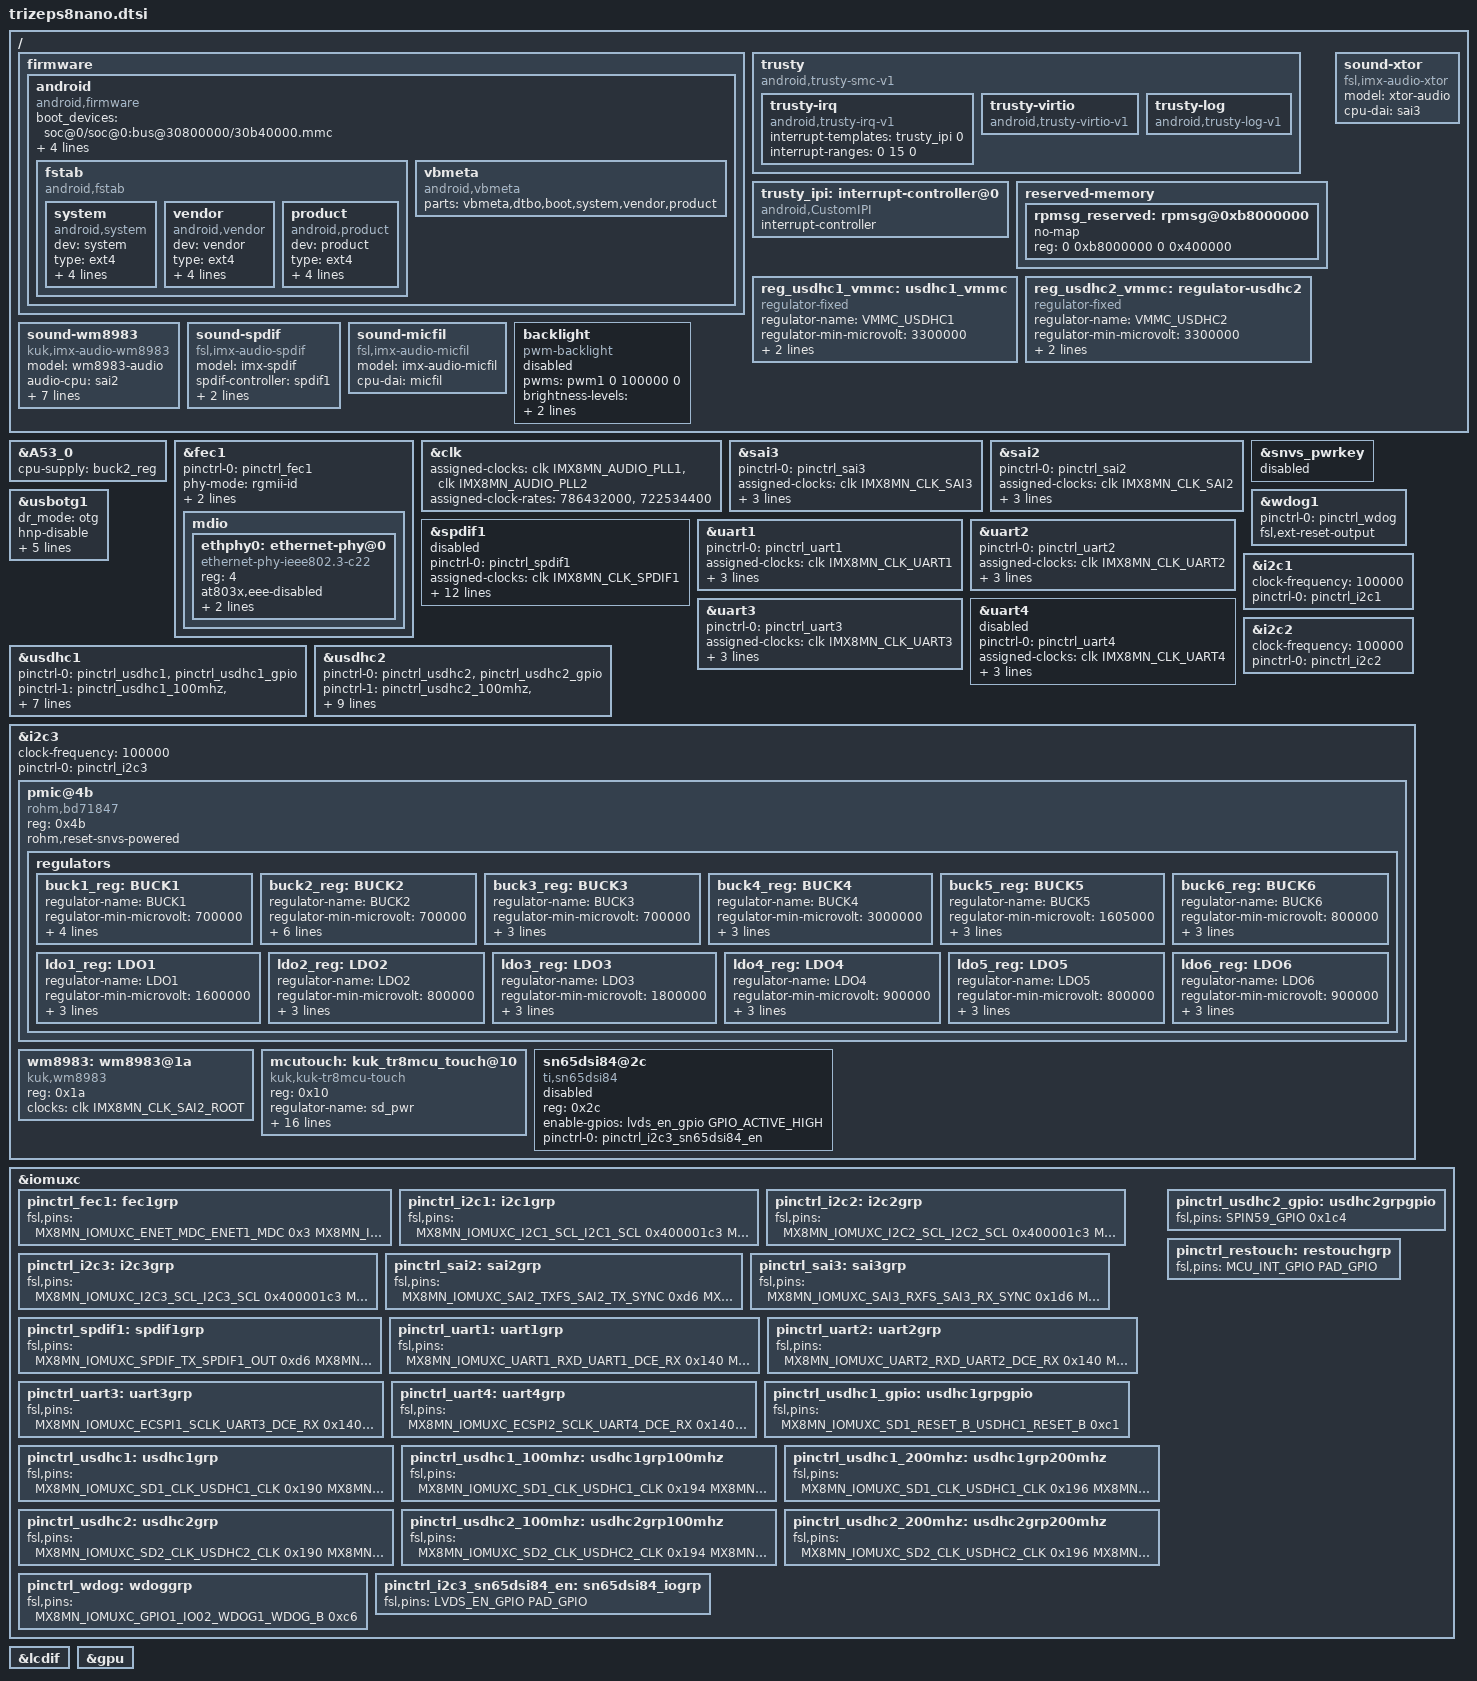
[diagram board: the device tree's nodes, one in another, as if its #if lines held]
/*
 * Copyright 2020 Keith & Koep GmbH
 */

 /*
Switches:
    TRIZEPS8NANO_USDHC1_VQMMC_MCU		For UHS: Control VQMMC voltage of internal uSD-Card.
    TRIZEPS8NANO_USDHC2_VQMMC_MCU		For UHS: Control VQMMC voltage of external uSD-Card. 
    There is only one VQMMC-switch on the Trizeps module. 
    Module with eMMC:   VQMMC of eMMC fixed to +1V8 and VQMMC of ext. uSD fixed to +3V3   
                        Special mounting exist to switch ext. uSD voltage: Use TRIZEPS8NANO_USDHC2_VQMMC_MCU in that case.
    Module with uSD:    VQMMC of int. uSD switchable (+3V3/+1V8) and VQMMC of ext. uSD fixed to +3V3. 
                        May use TRIZEPS8NANO_USDHC1_VQMMC_MCU to allow UHS.
    
    ETHERNET_ONLY_100MBIT				Reduce Ethernet to 100MBit in case extra lanes for 1GBit are not connected on the baseboard.

    TRIZEPS8NANO_BT_SCO_XTOR			Special audio-driver for Bluetooth.

*/

#include "imx8mn.dtsi"
#include "trizeps8nano-pinfunc.h"

#define TRIZEPS_HOGGRP_COMMON	

/ {
	firmware {
		android {
			compatible = "android,firmware";
			/* default emmc node used for GSI */
			boot_devices = "soc@0/soc@0:bus@30800000/30b40000.mmc";
			/* sd card node which used if androidboot.boot_device_root=mmcblk1 */
			boot_devices_mmcblk1 = "soc@0/soc@0:bus@30800000/30b40000.mmc";
			/* emmc node which used if androidboot.boot_device_root=mmcblk2 */
			boot_devices_mmcblk2 = "soc@0/soc@0:bus@30800000/30b40000.mmc";
			fstab {
				compatible = "android,fstab";
				system {
					compatible = "android,system";
					dev = "system";
					type = "ext4";
					mnt_flags = "noatime,errors=panic,ro,barrier=1,inode_readahead_blks=8";
					fsmgr_flags = "wait,slotselect,avb,avb_keys=/avb/q-gsi.avbpubkey:/avb/r-gsi.avbpubkey:/avb/s-gsi.avbpubkey,logical,first_stage_mount";
				};
				vendor {
					compatible = "android,vendor";
					dev = "vendor";
					type = "ext4";
					mnt_flags = "noatime,errors=panic,ro,barrier=1,inode_readahead_blks=8";
					fsmgr_flags = "wait,slotselect,avb,logical,first_stage_mount";
				};
				product {
					compatible = "android,product";
					dev = "product";
					type = "ext4";
					mnt_flags = "noatime,errors=panic,ro,barrier=1,inode_readahead_blks=8";
					fsmgr_flags = "wait,slotselect,avb,logical,first_stage_mount";
				};
			};
			vbmeta {
				/*we need use FirstStageMountVBootV2 if we enable avb*/
				compatible = "android,vbmeta";
				/*parts means the partition witch can be mount in first stage*/
				parts = "vbmeta,dtbo,boot,system,vendor,product";
			};
		};
	};
};

/ {
	trusty {
		compatible = "android,trusty-smc-v1";
		ranges;
		#address-cells = <2>;
		#size-cells = <2>;
		trusty-irq {
			compatible = "android,trusty-irq-v1";
			interrupt-templates = <&trusty_ipi 0>;
			interrupt-ranges = < 0 15 0>;
		};
		trusty-virtio {
			compatible = "android,trusty-virtio-v1";
		};
		trusty-log {
			compatible = "android,trusty-log-v1";
		};
	};
	trusty_ipi: interrupt-controller@0 {
		compatible = "android,CustomIPI";
		interrupt-controller;
		#interrupt-cells = <1>;
	};
};

/ {
	reserved-memory {
		#address-cells = <2>;
		#size-cells = <2>;
		ranges;

		rpmsg_reserved: rpmsg@0xb8000000 {
			no-map;
			reg = <0 0xb8000000 0 0x400000>;
		};
	};

	reg_usdhc1_vmmc: usdhc1_vmmc {
		compatible = "regulator-fixed";
		regulator-name = "VMMC_USDHC1";
		regulator-min-microvolt = <3300000>;
		regulator-max-microvolt = <3300000>;
		enable-active-high;
	};

	reg_usdhc2_vmmc: regulator-usdhc2 {
		compatible = "regulator-fixed";
		regulator-name = "VMMC_USDHC2";
		regulator-min-microvolt = <3300000>;
		regulator-max-microvolt = <3300000>;
		enable-active-high;
	};

#if defined(TRIZEPS8NANO_BT_SCO_XTOR) && (TRIZEPS8NANO_BT_SCO_XTOR==1)
	sound-xtor {
		compatible = "fsl,imx-audio-xtor";
		model = "xtor-audio";
		cpu-dai = <&sai3>;
		status = "okay";
	};
#else 
	bt_sco_codec: bt_sco_codec {
		#sound-dai-cells = <0>;
		compatible = "linux,bt-sco";
	};

	sound-bt-sco {
		compatible = "simple-audio-card";
		simple-audio-card,name = "bt-sco-audio";
		simple-audio-card,format = "i2s";
		simple-audio-card,bitclock-inversion;
		simple-audio-card,frame-master = <&btcpu>;
		simple-audio-card,bitclock-master = <&btcpu>;

		btcpu: simple-audio-card,cpu {
			sound-dai = <&sai2>;
			dai-tdm-slot-num = <2>;
			dai-tdm-slot-width = <16>;
		};

		simple-audio-card,codec {
			sound-dai = <&bt_sco_codec>;
		};
	};
#endif

	sound-wm8983 {
		compatible = "kuk,imx-audio-wm8983";
		model = "wm8983-audio";
		audio-cpu = <&sai2>;
		audio-codec = <&wm8983>;
		audio-routing =
			"Headphone Jack", "HPL",
			"Headphone Jack", "HPR",
			"Headphone Jack", "OUT4",
			"Speaker", "SPKL",
			"Speaker", "SPKR",
			"LineIn Jack", "L2",
			"LineIn Jack", "R2",
			"Microphone", "LIP",
			"Microphone", "LIN",
			"Microphone", "MICBIAS";
		codec-master;
	};

	sound-spdif {
		compatible = "fsl,imx-audio-spdif";
		model = "imx-spdif";
		spdif-controller = <&spdif1>;
		spdif-out;
		spdif-in;
	};

	sound-micfil {
		compatible = "fsl,imx-audio-micfil";
		model = "imx-audio-micfil";
		cpu-dai = <&micfil>;
	};

	backlight: backlight {
		compatible = "pwm-backlight";
		pwms = <&pwm1 0 100000 0>;
		brightness-levels = < 0  1  2  3  4  5  6  7  8  9
				     10 11 12 13 14 15 16 17 18 19
				     20 21 22 23 24 25 26 27 28 29
				     30 31 32 33 34 35 36 37 38 39
				     40 41 42 43 44 45 46 47 48 49
				     50 51 52 53 54 55 56 57 58 59
				     60 61 62 63 64 65 66 67 68 69
				     70 71 72 73 74 75 76 77 78 79
				     80 81 82 83 84 85 86 87 88 89
				     90 91 92 93 94 95 96 97 98 99
				    100>;
		default-brightness-level = <80>;
		status = "disabled";
 	};
};

&A53_0 {
	cpu-supply = <&buck2_reg>;
};

&fec1 {
	pinctrl-names = "default";
	pinctrl-0 = <&pinctrl_fec1>;
	phy-mode = "rgmii-id";
	phy-handle = <&ethphy0>;
	fsl,magic-packet;
	status = "okay";

	mdio {
		#address-cells = <1>;
		#size-cells = <0>;

		ethphy0: ethernet-phy@0 {
			compatible = "ethernet-phy-ieee802.3-c22";
			reg = <4>;
			at803x,eee-disabled;
			at803x,vddio-1p8v;
#if defined(ETHERNET_ONLY_100MBIT) && (ETHERNET_ONLY_100MBIT==1)
			at803x,100MBit;
#endif            
		};
	};
};

&clk {
	assigned-clocks = <&clk IMX8MN_AUDIO_PLL1>, <&clk IMX8MN_AUDIO_PLL2>;
	assigned-clock-rates = <786432000>, <722534400>;
};

&sai3 {
	pinctrl-names = "default";
	pinctrl-0 = <&pinctrl_sai3>;
	assigned-clocks = <&clk IMX8MN_CLK_SAI3>;
	assigned-clock-parents = <&clk IMX8MN_AUDIO_PLL1_OUT>;
	assigned-clock-rates = <49152000>;
	status = "okay";
};

&sai2 {
	#sound-dai-cells = <0>;
	pinctrl-names = "default";
	pinctrl-0 = <&pinctrl_sai2>;
	assigned-clocks = <&clk IMX8MN_CLK_SAI2>;
	assigned-clock-parents = <&clk IMX8MN_AUDIO_PLL1_OUT>;
	assigned-clock-rates = <24576000>;
	status = "okay";
};

&spdif1 {
	pinctrl-names = "default";
	pinctrl-0 = <&pinctrl_spdif1>;
	assigned-clocks = <&clk IMX8MN_CLK_SPDIF1>;
	assigned-clock-parents = <&clk IMX8MN_AUDIO_PLL1_OUT>;
	assigned-clock-rates = <24576000>;
	clocks = <&clk IMX8MN_CLK_AUDIO_AHB>, <&clk IMX8MN_CLK_24M>,
		<&clk IMX8MN_CLK_SPDIF1>, <&clk IMX8MN_CLK_DUMMY>,
		<&clk IMX8MN_CLK_DUMMY>, <&clk IMX8MN_CLK_DUMMY>,
		<&clk IMX8MN_CLK_AUDIO_AHB>, <&clk IMX8MN_CLK_DUMMY>,
		<&clk IMX8MN_CLK_DUMMY>, <&clk IMX8MN_CLK_DUMMY>,
		<&clk IMX8MN_AUDIO_PLL1_OUT>, <&clk IMX8MN_AUDIO_PLL2_OUT>;
	clock-names = "core", "rxtx0", "rxtx1", "rxtx2", "rxtx3",
		"rxtx4", "rxtx5", "rxtx6", "rxtx7", "spba", "pll8k", "pll11k";
	status = "disabled";
};

&snvs_pwrkey {
	status = "disabled";
};

&uart1 { /* FFUART */
	pinctrl-names = "default";
	pinctrl-0 = <&pinctrl_uart1>;
	assigned-clocks = <&clk IMX8MN_CLK_UART1>;
	assigned-clock-parents = <&clk IMX8MN_SYS_PLL1_80M>;
	fsl,uart-has-rtscts;
	status = "okay";
};

&uart2 { /* BTUART */
	pinctrl-names = "default";
	pinctrl-0 = <&pinctrl_uart2>;
	assigned-clocks = <&clk IMX8MN_CLK_UART2>;
	assigned-clock-parents = <&clk IMX8MN_SYS_PLL1_80M>;
    fsl,uart-has-rtscts;
	status = "okay";
};

&uart3 { /* STUART; optional internal for Bluetooth*/
	pinctrl-names = "default";
	pinctrl-0 = <&pinctrl_uart3>;
	assigned-clocks = <&clk IMX8MN_CLK_UART3>;
	assigned-clock-parents = <&clk IMX8MN_SYS_PLL1_80M>;
	fsl,uart-has-rtscts;
	status = "okay";
};

&uart4 { /* internal UART or SPI to FPGA and MCU*/
	pinctrl-names = "default";
	pinctrl-0 = <&pinctrl_uart4>;
	assigned-clocks = <&clk IMX8MN_CLK_UART4>;
	assigned-clock-parents = <&clk IMX8MN_SYS_PLL1_80M>;
	fsl,uart-has-rtscts;
	status = "disabled";
};


&usbotg1 {
	dr_mode = "otg";
	hnp-disable;
	srp-disable;
	adp-disable;
	usb-role-switch;
	picophy,pre-emp-curr-control = <3>;
	picophy,dc-vol-level-adjust = <7>;
	status = "okay";
};

&usdhc1 {
	pinctrl-names = "default", "state_100mhz", "state_200mhz";
	pinctrl-0 = <&pinctrl_usdhc1>, <&pinctrl_usdhc1_gpio>;
	pinctrl-1 = <&pinctrl_usdhc1_100mhz>, <&pinctrl_usdhc1_gpio>;
	pinctrl-2 = <&pinctrl_usdhc1_200mhz>, <&pinctrl_usdhc1_gpio>;
	bus-width = <8>;
	vmmc-supply = <&reg_usdhc1_vmmc>;
	non-removable;
#if defined(TRIZEPS8NANO_USDHC1_VQMMC_MCU) && (TRIZEPS8NANO_USDHC1_VQMMC_MCU==1)
    vqmmc-supply = <&mcutouch>;
#endif
	status = "okay";
};

&usdhc2 {
	pinctrl-names = "default", "state_100mhz", "state_200mhz";
	pinctrl-0 = <&pinctrl_usdhc2>, <&pinctrl_usdhc2_gpio>;
	pinctrl-1 = <&pinctrl_usdhc2_100mhz>, <&pinctrl_usdhc2_gpio>;
	pinctrl-2 = <&pinctrl_usdhc2_200mhz>, <&pinctrl_usdhc2_gpio>;
	cd-gpios = <spin59_gpio GPIO_ACTIVE_LOW>;
	bus-width = <4>;
	vmmc-supply = <&reg_usdhc2_vmmc>;
	pm-ignore-notify;
	keep-power-in-suspend;
#if defined(TRIZEPS8NANO_USDHC2_VQMMC_MCU) && (TRIZEPS8NANO_USDHC2_VQMMC_MCU==1)
    vqmmc-supply = <&mcutouch>;
#else
    no-1-8-v;
#endif    
	status = "okay";
};

&wdog1 {
	pinctrl-names = "default";
	pinctrl-0 = <&pinctrl_wdog>;
	fsl,ext-reset-output;
	status = "okay";
};

&i2c1 { /* Secondary I2C on SODIMM 94,96 */
	clock-frequency = <100000>;
	pinctrl-names = "default";
	pinctrl-0 = <&pinctrl_i2c1>;
	status = "okay";
};

&i2c2 { /* Secondary I2C on SODIMM 94,96 */
	clock-frequency = <100000>;
	pinctrl-names = "default";
	pinctrl-0 = <&pinctrl_i2c2>;
	status = "okay";
};

&i2c3 { /* Internal I2C */
	clock-frequency = <100000>;
	pinctrl-names = "default";
	pinctrl-0 = <&pinctrl_i2c3>;
	status = "okay";

	pmic@4b {
		compatible = "rohm,bd71847";
		reg = <0x4b>;
		rohm,reset-snvs-powered;

		regulators {
			buck1_reg: BUCK1 {  // VDD_SOC_0V8
				regulator-name = "BUCK1";
				regulator-min-microvolt = <700000>;
				regulator-max-microvolt = <1300000>;
				regulator-boot-on;
				regulator-always-on;
				regulator-ramp-delay = <1250>;
			};

			buck2_reg: BUCK2 {  // VDD_SOC_0V9
				regulator-name = "BUCK2";
				regulator-min-microvolt = <700000>;
				regulator-max-microvolt = <1300000>;
				regulator-boot-on;
				regulator-always-on;
				regulator-ramp-delay = <1250>;
				rohm,dvs-run-voltage = <1000000>;
				rohm,dvs-idle-voltage = <900000>;
			};

			buck3_reg: BUCK3 {  // VDD_DRAM_PU_0V9
				// BUCK5 in datasheet
				regulator-name = "BUCK3";
				regulator-min-microvolt = <700000>;
				regulator-max-microvolt = <1350000>;
				regulator-boot-on;
				regulator-always-on;
			};

			buck4_reg: BUCK4 {  // +3V3_AUX
				// BUCK6 in datasheet
				regulator-name = "BUCK4";
				regulator-min-microvolt = <3000000>;
				regulator-max-microvolt = <3300000>;
				regulator-boot-on;
				regulator-always-on;
			};

			buck5_reg: BUCK5 {  // VDD_1V8
				// BUCK7 in datasheet
				regulator-name = "BUCK5";
				regulator-min-microvolt = <1605000>;
				regulator-max-microvolt = <1995000>;
				regulator-boot-on;
				regulator-always-on;
			};

			buck6_reg: BUCK6 {  // NVCC_DRAM_1V1
				// BUCK8 in datasheet
				regulator-name = "BUCK6";
				regulator-min-microvolt = <800000>;
				regulator-max-microvolt = <1400000>;
				regulator-boot-on;
				regulator-always-on;
			};

			ldo1_reg: LDO1 {    // NVCC_SNVS_1V8
				regulator-name = "LDO1";
				regulator-min-microvolt = <1600000>;
				regulator-max-microvolt = <1900000>;
				regulator-boot-on;
				regulator-always-on;
			};

			ldo2_reg: LDO2 {    // VDD_SNVS_0V8
				regulator-name = "LDO2";
				regulator-min-microvolt = <800000>;
				regulator-max-microvolt = <900000>;
				regulator-boot-on;
				regulator-always-on;
			};

			ldo3_reg: LDO3 {    // VDDA_1V8
				regulator-name = "LDO3";
				regulator-min-microvolt = <1800000>;
				regulator-max-microvolt = <3300000>;
				regulator-boot-on;
				regulator-always-on;
			};

			ldo4_reg: LDO4 {    // VDD_PHY_0V9
				regulator-name = "LDO4";
				regulator-min-microvolt = <900000>;
				regulator-max-microvolt = <1800000>;
				regulator-boot-on;
				regulator-always-on;
			};

			ldo5_reg: LDO5 {    // VDD_FPGA_MIPI
				regulator-name = "LDO5";
				regulator-min-microvolt = <800000>;
				regulator-max-microvolt = <3300000>;
				regulator-boot-on;
				regulator-always-on;
			};

			ldo6_reg: LDO6 {    // VDD_PHY_1V2
				regulator-name = "LDO6";
				regulator-min-microvolt = <900000>;
				regulator-max-microvolt = <1800000>;
				regulator-boot-on;
				regulator-always-on;
			};
		};
	};

	wm8983: wm8983@1a {	/* Audio-Codec */
		compatible = "kuk,wm8983";
		reg = <0x1a>;
		clocks = <&clk IMX8MN_CLK_SAI2_ROOT>;
		clock-names = "mclk";		
	};

	mcutouch: kuk_tr8mcu_touch@10 { /* Kinetis MCU and touch-controller */
		compatible = "kuk,kuk-tr8mcu-touch";
		reg = <0x10>;
        regulator-name = "sd_pwr";
        regulator-min-microvolt = <1800000>;
        regulator-max-microvolt = <3300000>;
		pinctrl-names = "default";
		pinctrl-0 = <&pinctrl_restouch>;
		interrupts-extended = <&gpio2 20 IRQ_TYPE_LEVEL_LOW>;	        	
		xscale              = <800>;
		yscale              = <480>;
		xmin                = <306>;
		xmax                = <3781>;
        ymin                = <692>;
        ymax                = <3459>;
        settle              = <10>;
		average             = <25>;
		yreverse            = "true" ;
        enable_touch        = "false";
		linux,wakeup;
	};    

	sn65dsi84@2c {
		status = "disabled";
		compatible = "ti,sn65dsi84";
		reg = <0x2c>;
		enable-gpios =<lvds_en_gpio GPIO_ACTIVE_HIGH>;

		pinctrl-names = "default";
		pinctrl-0 = <&pinctrl_i2c3_sn65dsi84_en>;
	};        
};


&iomuxc {
	pinctrl-names = "default";

	pinctrl_fec1: fec1grp {
		fsl,pins = <
			MX8MN_IOMUXC_ENET_MDC_ENET1_MDC			0x3
			MX8MN_IOMUXC_ENET_MDIO_ENET1_MDIO		0x3
			MX8MN_IOMUXC_ENET_TD3_ENET1_RGMII_TD3		0x1f
			MX8MN_IOMUXC_ENET_TD2_ENET1_RGMII_TD2		0x1f
			MX8MN_IOMUXC_ENET_TD1_ENET1_RGMII_TD1		0x1f
			MX8MN_IOMUXC_ENET_TD0_ENET1_RGMII_TD0		0x1f
			MX8MN_IOMUXC_ENET_RD3_ENET1_RGMII_RD3		0x91
			MX8MN_IOMUXC_ENET_RD2_ENET1_RGMII_RD2		0x91
			MX8MN_IOMUXC_ENET_RD1_ENET1_RGMII_RD1		0x91
			MX8MN_IOMUXC_ENET_RD0_ENET1_RGMII_RD0		0x91
			MX8MN_IOMUXC_ENET_TXC_ENET1_RGMII_TXC		0x1f
			MX8MN_IOMUXC_ENET_RXC_ENET1_RGMII_RXC		0x91
			MX8MN_IOMUXC_ENET_RX_CTL_ENET1_RGMII_RX_CTL	0x91
			MX8MN_IOMUXC_ENET_TX_CTL_ENET1_RGMII_TX_CTL	0x1f
			MX8MN_IOMUXC_GPIO1_IO09_GPIO1_IO9		0x19
		>;
	};


	pinctrl_i2c1: i2c1grp {
		fsl,pins = <
			MX8MN_IOMUXC_I2C1_SCL_I2C1_SCL			0x400001c3
			MX8MN_IOMUXC_I2C1_SDA_I2C1_SDA			0x400001c3
		>;
	};

	pinctrl_i2c2: i2c2grp {
		fsl,pins = <
			MX8MN_IOMUXC_I2C2_SCL_I2C2_SCL			0x400001c3
			MX8MN_IOMUXC_I2C2_SDA_I2C2_SDA			0x400001c3
		>;
	};

	pinctrl_i2c3: i2c3grp {
		fsl,pins = <
			MX8MN_IOMUXC_I2C3_SCL_I2C3_SCL			0x400001c3
			MX8MN_IOMUXC_I2C3_SDA_I2C3_SDA			0x400001c3
		>;
	};

	pinctrl_sai2: sai2grp {
		fsl,pins = <
			MX8MN_IOMUXC_SAI2_TXFS_SAI2_TX_SYNC	0xd6
			MX8MN_IOMUXC_SAI2_TXC_SAI2_TX_BCLK	0xd6
			MX8MN_IOMUXC_SAI2_MCLK_SAI2_MCLK	0xd6
			MX8MN_IOMUXC_SAI2_TXD0_SAI2_TX_DATA0	0xd6
			MX8MN_IOMUXC_SAI2_RXD0_SAI2_RX_DATA0	0xd6			
		>;
    };

	pinctrl_sai3: sai3grp {
		fsl,pins = <
			MX8MN_IOMUXC_SAI3_RXFS_SAI3_RX_SYNC     0x1d6
			MX8MN_IOMUXC_SAI3_RXC_SAI3_RX_BCLK      0x1d6
			MX8MN_IOMUXC_SAI3_RXD_SAI3_RX_DATA0     0x196
			MX8MN_IOMUXC_SAI3_TXD_SAI3_TX_DATA0     0x196
		>;
	};


	pinctrl_spdif1: spdif1grp {
		fsl,pins = <
			MX8MN_IOMUXC_SPDIF_TX_SPDIF1_OUT	0xd6
			MX8MN_IOMUXC_SPDIF_RX_SPDIF1_IN		0xd6
		>;
	};


	pinctrl_uart1: uart1grp {
		fsl,pins = <
			MX8MN_IOMUXC_UART1_RXD_UART1_DCE_RX	0x140
			MX8MN_IOMUXC_UART1_TXD_UART1_DCE_TX	0x140
		>;
	};

	pinctrl_uart2: uart2grp {
		fsl,pins = <
			MX8MN_IOMUXC_UART2_RXD_UART2_DCE_RX	0x140
			MX8MN_IOMUXC_UART2_TXD_UART2_DCE_TX	0x140
			MX8MN_IOMUXC_UART4_RXD_UART2_DCE_CTS_B  0x140     /* RTS */
			MX8MN_IOMUXC_UART4_TXD_UART2_DCE_RTS_B  0x140     /* CTS */
		>;
	};

	pinctrl_uart3: uart3grp {
		fsl,pins = <
			MX8MN_IOMUXC_ECSPI1_SCLK_UART3_DCE_RX		0x140  /* SCHEMA/LAYOUT: RXD */
			MX8MN_IOMUXC_ECSPI1_MISO_UART3_DCE_CTS_B	0x140  /* SCHEMA/LAYOUT: RTS */
			MX8MN_IOMUXC_ECSPI1_MOSI_UART3_DCE_TX		0x140  /* SCHEMA/LAYOUT: TXD */
			MX8MN_IOMUXC_ECSPI1_SS0_UART3_DCE_RTS_B		0x140  /* SCHEMA/LAYOUT: CTS */
		>;
	};

	pinctrl_uart4: uart4grp {
		fsl,pins = <
			MX8MN_IOMUXC_ECSPI2_SCLK_UART4_DCE_RX		0x140
			MX8MN_IOMUXC_ECSPI2_MOSI_UART4_DCE_TX		0x140
			MX8MN_IOMUXC_ECSPI2_SS0_UART4_DCE_RTS_B         0x140
			MX8MN_IOMUXC_ECSPI2_MISO_UART4_DCE_CTS_B	0x140
		>;
	};

	pinctrl_usdhc1_gpio: usdhc1grpgpio {
		fsl,pins = <
			MX8MN_IOMUXC_SD1_RESET_B_USDHC1_RESET_B	0xc1
		>;
	};

	pinctrl_usdhc1: usdhc1grp {
		fsl,pins = <
			MX8MN_IOMUXC_SD1_CLK_USDHC1_CLK		0x190
			MX8MN_IOMUXC_SD1_CMD_USDHC1_CMD		0x1d0
			MX8MN_IOMUXC_SD1_DATA0_USDHC1_DATA0	0x1d0
			MX8MN_IOMUXC_SD1_DATA1_USDHC1_DATA1	0x1d0
			MX8MN_IOMUXC_SD1_DATA2_USDHC1_DATA2	0x1d0
			MX8MN_IOMUXC_SD1_DATA3_USDHC1_DATA3	0x1d0
			MX8MN_IOMUXC_SD1_DATA4_USDHC1_DATA4	0x1d0
			MX8MN_IOMUXC_SD1_DATA5_USDHC1_DATA5	0x1d0
			MX8MN_IOMUXC_SD1_DATA6_USDHC1_DATA6	0x1d0
			MX8MN_IOMUXC_SD1_DATA7_USDHC1_DATA7	0x1d0
			MX8MN_IOMUXC_SD1_STROBE_USDHC1_STROBE	0x190			
		>;
	};

	pinctrl_usdhc1_100mhz: usdhc1grp100mhz {
		fsl,pins = <
			MX8MN_IOMUXC_SD1_CLK_USDHC1_CLK		0x194
			MX8MN_IOMUXC_SD1_CMD_USDHC1_CMD		0x1d4
			MX8MN_IOMUXC_SD1_DATA0_USDHC1_DATA0	0x1d4
			MX8MN_IOMUXC_SD1_DATA1_USDHC1_DATA1	0x1d4
			MX8MN_IOMUXC_SD1_DATA2_USDHC1_DATA2	0x1d4
			MX8MN_IOMUXC_SD1_DATA3_USDHC1_DATA3	0x1d4
			MX8MN_IOMUXC_SD1_DATA4_USDHC1_DATA4	0x1d4
			MX8MN_IOMUXC_SD1_DATA5_USDHC1_DATA5	0x1d4
			MX8MN_IOMUXC_SD1_DATA6_USDHC1_DATA6	0x1d4
			MX8MN_IOMUXC_SD1_DATA7_USDHC1_DATA7	0x1d4
			MX8MN_IOMUXC_SD1_STROBE_USDHC1_STROBE	0x194
		>;
	};

	pinctrl_usdhc1_200mhz: usdhc1grp200mhz {
		fsl,pins = <
			MX8MN_IOMUXC_SD1_CLK_USDHC1_CLK		0x196
			MX8MN_IOMUXC_SD1_CMD_USDHC1_CMD		0x1d6
			MX8MN_IOMUXC_SD1_DATA0_USDHC1_DATA0	0x1d6
			MX8MN_IOMUXC_SD1_DATA1_USDHC1_DATA1	0x1d6
			MX8MN_IOMUXC_SD1_DATA2_USDHC1_DATA2	0x1d6
			MX8MN_IOMUXC_SD1_DATA3_USDHC1_DATA3	0x1d6
			MX8MN_IOMUXC_SD1_DATA4_USDHC1_DATA4	0x1d6
			MX8MN_IOMUXC_SD1_DATA5_USDHC1_DATA5	0x1d6
			MX8MN_IOMUXC_SD1_DATA6_USDHC1_DATA6	0x1d6
			MX8MN_IOMUXC_SD1_DATA7_USDHC1_DATA7	0x1d6
			MX8MN_IOMUXC_SD1_STROBE_USDHC1_STROBE	0x196
		>;
	};

	pinctrl_usdhc2_gpio: usdhc2grpgpio {
		fsl,pins = <
			SPIN59_GPIO	                        0x1c4
		>;
	};

	pinctrl_usdhc2: usdhc2grp {
		fsl,pins = <
			MX8MN_IOMUXC_SD2_CLK_USDHC2_CLK		0x190
			MX8MN_IOMUXC_SD2_CMD_USDHC2_CMD		0x1d0
			MX8MN_IOMUXC_SD2_DATA0_USDHC2_DATA0	0x1d0
			MX8MN_IOMUXC_SD2_DATA1_USDHC2_DATA1	0x1d0
			MX8MN_IOMUXC_SD2_DATA2_USDHC2_DATA2	0x1d0
			MX8MN_IOMUXC_SD2_DATA3_USDHC2_DATA3	0x1d0
		>;
	};

	pinctrl_usdhc2_100mhz: usdhc2grp100mhz {
		fsl,pins = <
			MX8MN_IOMUXC_SD2_CLK_USDHC2_CLK		0x194
			MX8MN_IOMUXC_SD2_CMD_USDHC2_CMD		0x1d4
			MX8MN_IOMUXC_SD2_DATA0_USDHC2_DATA0	0x1d4
			MX8MN_IOMUXC_SD2_DATA1_USDHC2_DATA1	0x1d4
			MX8MN_IOMUXC_SD2_DATA2_USDHC2_DATA2	0x1d4
			MX8MN_IOMUXC_SD2_DATA3_USDHC2_DATA3	0x1d4
		>;
	};

	pinctrl_usdhc2_200mhz: usdhc2grp200mhz {
		fsl,pins = <
			MX8MN_IOMUXC_SD2_CLK_USDHC2_CLK		0x196
			MX8MN_IOMUXC_SD2_CMD_USDHC2_CMD		0x1d6
			MX8MN_IOMUXC_SD2_DATA0_USDHC2_DATA0	0x1d6
			MX8MN_IOMUXC_SD2_DATA1_USDHC2_DATA1	0x1d6
			MX8MN_IOMUXC_SD2_DATA2_USDHC2_DATA2	0x1d6
			MX8MN_IOMUXC_SD2_DATA3_USDHC2_DATA3	0x1d6
		>;
	};

	pinctrl_wdog: wdoggrp {
		fsl,pins = <
			MX8MN_IOMUXC_GPIO1_IO02_WDOG1_WDOG_B	0xc6
		>;
	};        

	pinctrl_restouch: restouchgrp {
		fsl,pins = < MCU_INT_GPIO       PAD_GPIO >; /* MCU Interrupt */
	};

	pinctrl_i2c3_sn65dsi84_en: sn65dsi84_iogrp {
		fsl,pins = < LVDS_EN_GPIO  PAD_GPIO  >; /* Myon internal LVDS Enable and external Pin0-72 */
	};
};

&lcdif {
	status = "okay";
};

&gpu {
	status = "okay";
};
